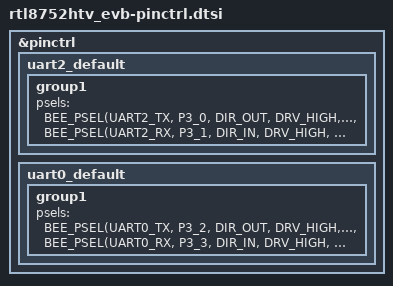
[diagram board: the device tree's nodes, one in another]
/*
 * Copyright(c) 2024, Realtek Semiconductor Corporation.
 * SPDX-License-Identifier: Apache-2.0
 */

#include <dt-bindings/pinctrl/rtl8752h-pinctrl.h>

&pinctrl {
	uart2_default: uart2_default {
		group1 {
			psels = <BEE_PSEL(UART2_TX, P3_0, DIR_OUT, DRV_HIGH, PULL_UP)>,
			<BEE_PSEL(UART2_RX, P3_1, DIR_IN, DRV_HIGH, PULL_UP)>;
		};
	};
	uart0_default: uart0_default {
		group1 {
			psels = <BEE_PSEL(UART0_TX, P3_2, DIR_OUT, DRV_HIGH, PULL_UP)>,
			<BEE_PSEL(UART0_RX, P3_3, DIR_IN, DRV_HIGH, PULL_UP)>;
		};
	};
};
